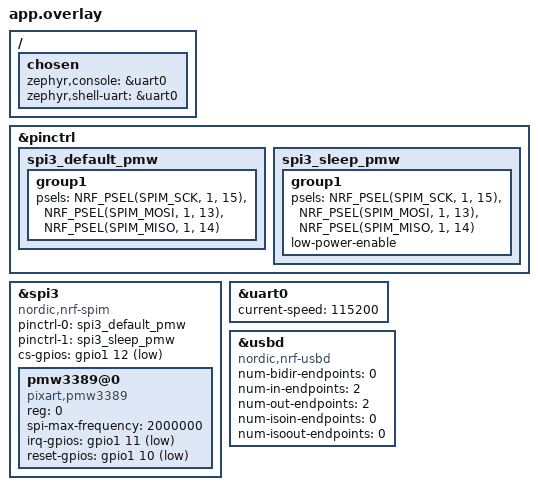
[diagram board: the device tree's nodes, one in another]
/*
 * nRF52840 DK + PMW3389 Sensor Debug Configuration
 *
 * Wire the PMW3389 breakout / PCB to the DK Arduino header:
 *
 *   PMW3389 Signal   DK Arduino Pin   nRF52840 GPIO
 *   ──────────────   ──────────────   ─────────────
 *   SCK              D13              P1.15
 *   MOSI             D11              P1.13
 *   MISO             D12              P1.14
 *   NCS  (CS)        D10              P1.12
 *   MOTION (IRQ)     D9               P1.11
 *   NRESET           D8               P1.10
 *   VDD              3V3              (3.3 V rail)
 *   GND              GND
 *
 * SPDX-License-Identifier: LicenseRef-Nordic-5-Clause
 */

#include "app_common.dtsi"

/ {
	chosen {
		zephyr,console = &uart0;
		zephyr,shell-uart = &uart0;
	};
};

/* ── SPI pinctrl for PMW3389 on the Arduino header ────────────────────── */
&pinctrl {
	spi3_default_pmw: spi3_default_pmw {
		group1 {
			psels = <NRF_PSEL(SPIM_SCK,  1, 15)>,
			        <NRF_PSEL(SPIM_MOSI, 1, 13)>,
			        <NRF_PSEL(SPIM_MISO, 1, 14)>;
		};
	};
	spi3_sleep_pmw: spi3_sleep_pmw {
		group1 {
			psels = <NRF_PSEL(SPIM_SCK,  1, 15)>,
			        <NRF_PSEL(SPIM_MOSI, 1, 13)>,
			        <NRF_PSEL(SPIM_MISO, 1, 14)>;
			low-power-enable;
		};
	};
};

/* ── SPI3 bus with PMW3389 sensor ─────────────────────────────────────── */
&spi3 {
	compatible = "nordic,nrf-spim";
	status = "okay";
	pinctrl-0 = <&spi3_default_pmw>;
	pinctrl-1 = <&spi3_sleep_pmw>;
	pinctrl-names = "default", "sleep";

	/* NCS / Chip-Select: D10 = P1.12, active-low */
	cs-gpios = <&gpio1 12 GPIO_ACTIVE_LOW>;

	pmw3389@0 {
		compatible = "pixart,pmw3389";
		reg = <0>;
		spi-max-frequency = <2000000>;  /* 2 MHz – conservative */

		/* MOTION / IRQ: D9 = P1.11, active-low */
		irq-gpios = <&gpio1 11 (GPIO_ACTIVE_LOW | GPIO_PULL_UP)>;

		/* NRESET: D8 = P1.10, active-low hardware reset */
		reset-gpios = <&gpio1 10 GPIO_ACTIVE_LOW>;
	};
};

/* ── UART0 for debug console (DK J-Link USB → /dev/ttyACM*) ──────────── */
&uart0 {
	status = "okay";
	current-speed = <115200>;
};

/* ── USB HID support ──────────────────────────────────────────────────── */
&usbd {
	compatible = "nordic,nrf-usbd";
	status = "okay";
	num-bidir-endpoints = <0>;
	num-in-endpoints = <2>;
	num-out-endpoints = <2>;
	num-isoin-endpoints = <0>;
	num-isoout-endpoints = <0>;
};
